# Watchdog_Timer_1 register map
Vendor: Texas Instruments
Peripheral module from a debugger description file (folder msp430).
Registers are 16-bit, read-write, reset 0x0 unless marked. A register's access mark holds for its fields unless they carry their own. Offsets are as the file gives them; lines under a group give offsets from that group; [hi:lo] are bit positions; {n}, {i} and the like mark numbered series; 'fields as' and 'values as' point back to an identical list; <NAME> marks a mode.

## Watchdog_Timer
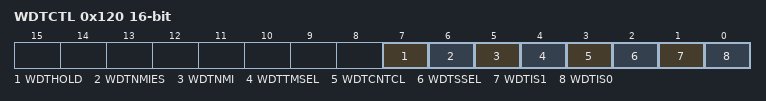
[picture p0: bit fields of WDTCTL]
0x120 WDTCTL — Watchdog Timer Control
  [7] WDTHOLD, [6] WDTNMIES, [5] WDTNMI, [4] WDTTMSEL, [3] WDTCNTCL, [2] WDTSSEL, [1] WDTIS1, [0] WDTIS0
